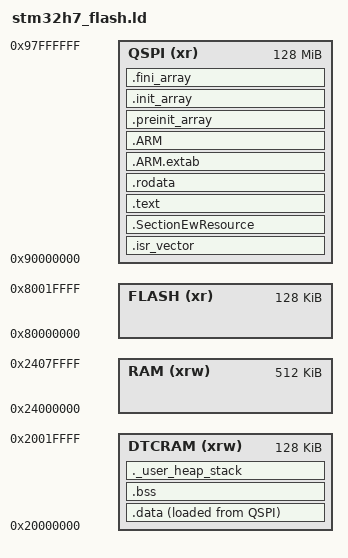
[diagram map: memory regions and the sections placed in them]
/*
*****************************************************************************
**

**  File        : stm32h7_flash.ld
**
**  Abstract    : Linker script for STM32H750 Discovery board with
**                 128 kByte Flash
**                 128 kByte DTCM-RAM
**                 512 kByte AXI-RAM (D1 domain)
**                 288 kByte SRAM (D2 domain) - not used
**                  64 kByte SRAM (D3 domain) - not used
**                 128 MByte QSPI-Flash
**
**                Set heap size, stack size and stack location according
**                to application requirements.
**
**                Set memory bank area and size if external memory is used.
**
**  Target      : STMicroelectronics STM32
**
**
*****************************************************************************
*/

/* Entry Point */
ENTRY(Reset_Handler)

/* Highest address of the user mode stack */
_estack = 0x2001FFF0;    /* end of RAM */

/* Generate a link error if heap and stack don't fit into RAM */
_Min_Heap_Size = 0x200;     /* required amount of heap - not important because we use own memory manager */

_Min_Stack_Size = 0x2000;    /* required amount of stack */

/* Specify the memory areas */
MEMORY
{
  FLASH (xr)  : ORIGIN = 0x80000000, LENGTH = 128k
  DTCRAM (xrw): ORIGIN = 0x20000000, LENGTH = 128K
  RAM (xrw)   : ORIGIN = 0x24000000, LENGTH = 512K
  QSPI (xr)   : ORIGIN = 0x90000000, LENGTH = 128M
}

/* Define output sections */
SECTIONS
{
  /* The startup code goes first into FLASH */
  .isr_vector :
  {
    . = ALIGN(4);
    KEEP(*(.isr_vector)) /* Startup code */
    . = ALIGN(4);
  } >QSPI

  /* The Embedded Wizard resource rodata goes into external FLASH */
  .SectionEwResource :
  {
    . = ALIGN(4);
    *(.SectionEwResource)
    . = ALIGN(4);
  } >QSPI


  /* The program code and other data goes into external FLASH */
  .text :
  {
    . = ALIGN(4);
    *(.text)           /* .text sections (code) */
    *(.text*)          /* .text* sections (code) */
    *(.glue_7)         /* glue arm to thumb code */
    *(.glue_7t)        /* glue thumb to arm code */
    *(.eh_frame)

    KEEP (*(.init))
    KEEP (*(.fini))

    . = ALIGN(4);
    _etext = .;        /* define a global symbols at end of code */
  } >QSPI

  /* Constant data goes into external FLASH */
  .rodata :
  {
    . = ALIGN(4);
    *(.rodata)         /* .rodata sections (constants, strings, etc.) */
    *(.rodata*)        /* .rodata* sections (constants, strings, etc.) */
    . = ALIGN(4);
  } >QSPI

  .ARM.extab   : { *(.ARM.extab* .gnu.linkonce.armextab.*) } >QSPI
  .ARM : {
    __exidx_start = .;
    *(.ARM.exidx*)
    __exidx_end = .;
  } >QSPI

  .preinit_array     :
  {
    PROVIDE_HIDDEN (__preinit_array_start = .);
    KEEP (*(.preinit_array*))
    PROVIDE_HIDDEN (__preinit_array_end = .);
  } >QSPI
  .init_array :
  {
    PROVIDE_HIDDEN (__init_array_start = .);
    KEEP (*(SORT(.init_array.*)))
    KEEP (*(.init_array*))
    PROVIDE_HIDDEN (__init_array_end = .);
  } >QSPI
  .fini_array :
  {
    PROVIDE_HIDDEN (__fini_array_start = .);
    KEEP (*(SORT(.fini_array.*)))
    KEEP (*(.fini_array*))
    PROVIDE_HIDDEN (__fini_array_end = .);
  } >QSPI

  /* used by the startup to initialize data */
  _sidata = LOADADDR(.data);

  /* Initialized data sections goes into RAM, load LMA copy after code */
  .data :
  {
    . = ALIGN(4);
    _sdata = .;        /* create a global symbol at data start */
    *(.data)           /* .data sections */
    *(.data*)          /* .data* sections */

    . = ALIGN(4);
    _edata = .;        /* define a global symbol at data end */
  } >DTCRAM AT> QSPI


  /* Uninitialized data section */
  . = ALIGN(4);
  .bss :
  {
    /* This is used by the startup in order to initialize the .bss secion */
    _sbss = .;         /* define a global symbol at bss start */
    __bss_start__ = _sbss;
    *(.bss)
    *(.bss*)
    *(COMMON)

    . = ALIGN(4);
    _ebss = .;         /* define a global symbol at bss end */
    __bss_end__ = _ebss;
  } >DTCRAM

  /* User_heap_stack section, used to check that there is enough RAM left */
  ._user_heap_stack :
  {
    . = ALIGN(8);
    PROVIDE ( end = . );
    PROVIDE ( _end = . );
    . = . + _Min_Heap_Size;
    . = . + _Min_Stack_Size;
    . = ALIGN(8);
  } >DTCRAM



  /* Remove information from the standard libraries */
  /DISCARD/ :
  {
    libc.a ( * )
    libm.a ( * )
    libgcc.a ( * )
  }

  .ARM.attributes 0 : { *(.ARM.attributes) }
}


